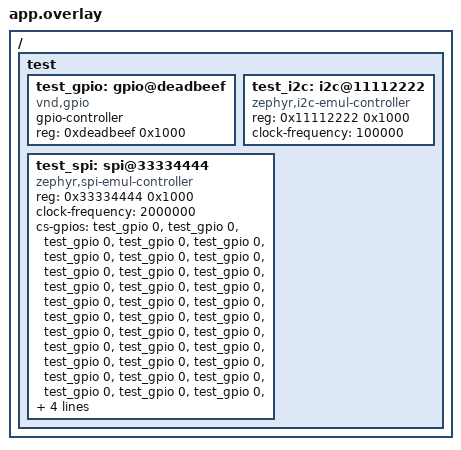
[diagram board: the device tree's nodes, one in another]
/*
 * Copyright (c) 2020, Linaro Ltd.
 *
 * SPDX-License-Identifier: Apache-2.0
 *
 * Application overlay for testing driver builds
 *
 * Names in this file should be chosen in a way that won't conflict
 * with real-world devicetree nodes, to allow these tests to run on
 * (and be extended to test) real hardware.
 */

/ {
	test {
		#address-cells = <1>;
		#size-cells = <1>;

		test_gpio: gpio@deadbeef {
			compatible = "vnd,gpio";
			gpio-controller;
			reg = <0xdeadbeef 0x1000>;
			#gpio-cells = <0x2>;
			status = "okay";
		};

		test_i2c: i2c@11112222 {
			#address-cells = <1>;
			#size-cells = <0>;
			compatible = "zephyr,i2c-emul-controller";
			reg = <0x11112222 0x1000>;
			status = "okay";
			clock-frequency = <100000>;

			#include "i2c.dtsi"
		};

		test_spi: spi@33334444 {
			#address-cells = <1>;
			#size-cells = <0>;
			compatible = "zephyr,spi-emul-controller";
			reg = <0x33334444 0x1000>;
			status = "okay";
			clock-frequency = <2000000>;

			/* one entry for every devices at spi.dtsi */
			cs-gpios = <&test_gpio 0 0>,	/* 0x00 */
				   <&test_gpio 0 0>,
				   <&test_gpio 0 0>,
				   <&test_gpio 0 0>,
				   <&test_gpio 0 0>,
				   <&test_gpio 0 0>,
				   <&test_gpio 0 0>,
				   <&test_gpio 0 0>,
				   <&test_gpio 0 0>,
				   <&test_gpio 0 0>,
				   <&test_gpio 0 0>,
				   <&test_gpio 0 0>,
				   <&test_gpio 0 0>,
				   <&test_gpio 0 0>,
				   <&test_gpio 0 0>,
				   <&test_gpio 0 0>,
				   <&test_gpio 0 0>,	/* 0x10 */
				   <&test_gpio 0 0>,
				   <&test_gpio 0 0>,
				   <&test_gpio 0 0>,
				   <&test_gpio 0 0>,
				   <&test_gpio 0 0>,
				   <&test_gpio 0 0>,
				   <&test_gpio 0 0>,
				   <&test_gpio 0 0>,
				   <&test_gpio 0 0>,
				   <&test_gpio 0 0>,
				   <&test_gpio 0 0>,
				   <&test_gpio 0 0>,
				   <&test_gpio 0 0>,
				   <&test_gpio 0 0>,
				   <&test_gpio 0 0>,
				   <&test_gpio 0 0>,	/* 0x20 */
				   <&test_gpio 0 0>,
				   <&test_gpio 0 0>,
				   <&test_gpio 0 0>,
				   <&test_gpio 0 0>,
				   <&test_gpio 0 0>,
				   <&test_gpio 0 0>,
				   <&test_gpio 0 0>,
				   <&test_gpio 0 0>,
				   <&test_gpio 0 0>,
				   <&test_gpio 0 0>,
				   <&test_gpio 0 0>,
				   <&test_gpio 0 0>,
				   <&test_gpio 0 0>,
				   <&test_gpio 0 0>;	/* 0x2e */

			#include "spi.dtsi"
		};

		#include "other.dtsi"
	};
};
